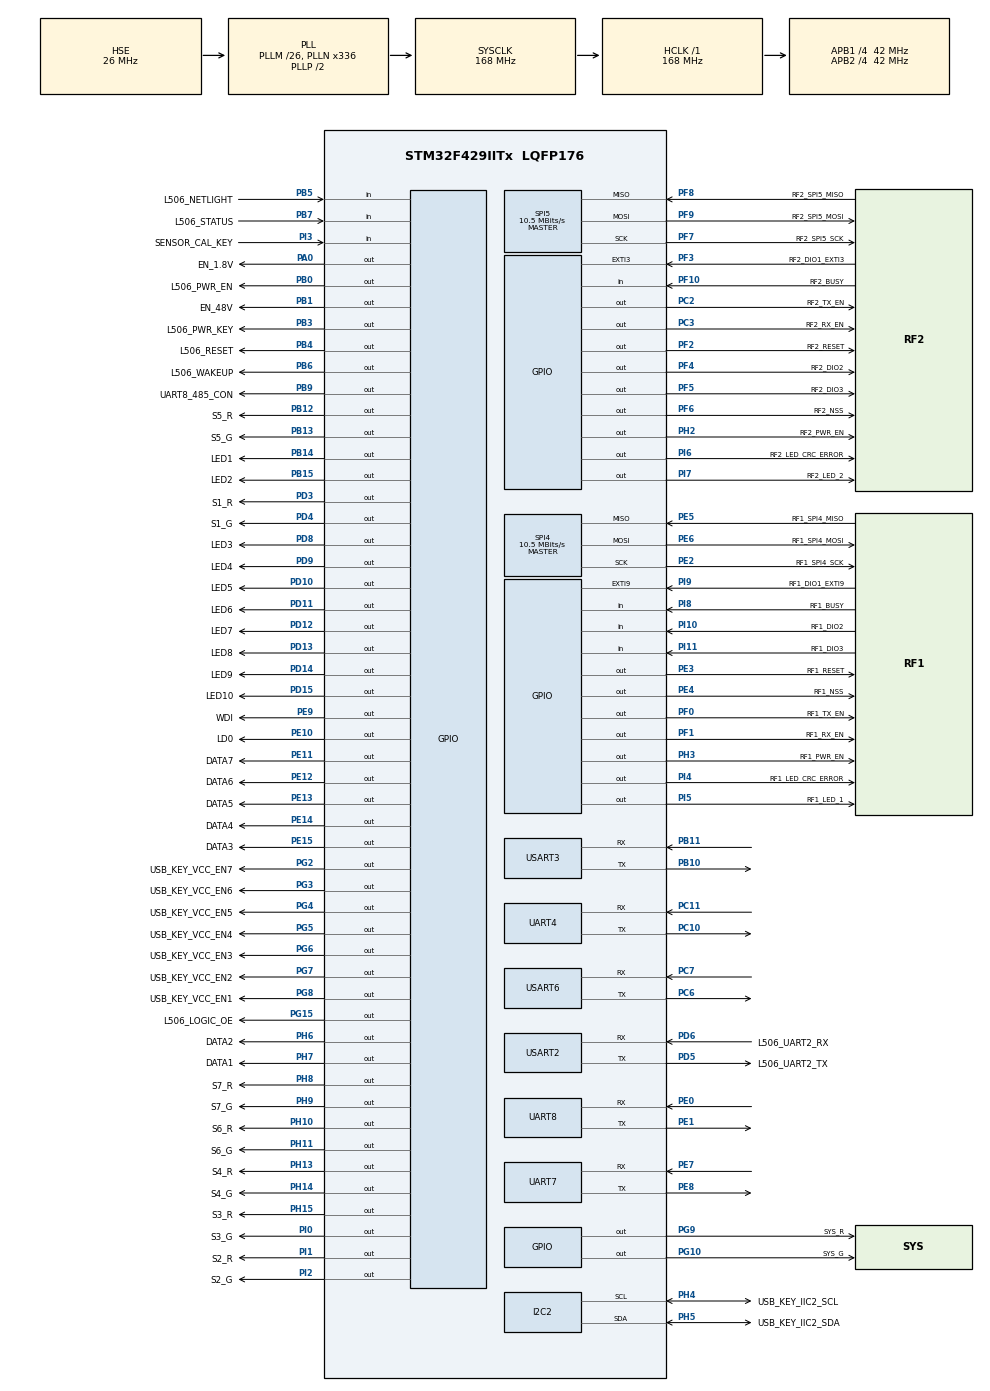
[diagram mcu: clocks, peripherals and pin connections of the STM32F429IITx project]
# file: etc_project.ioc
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Dma.Request0=USART6_RX
Dma.Request1=USART6_TX
Dma.Request2=USART3_TX
Dma.Request3=USART3_RX
Dma.Request4=USART2_RX
Dma.Request5=USART2_TX
Dma.Request6=UART4_RX
Dma.Request7=UART4_TX
Dma.UART4_RX.6.Direction=DMA_PERIPH_TO_MEMORY
Dma.UART4_RX.6.FIFOMode=DMA_FIFOMODE_DISABLE
Dma.UART4_RX.6.Instance=DMA1_Stream2
Dma.UART4_RX.6.MemDataAlignment=DMA_MDATAALIGN_BYTE
Dma.UART4_RX.6.MemInc=DMA_MINC_ENABLE
Dma.UART4_RX.6.Mode=DMA_NORMAL
Dma.UART4_RX.6.PeriphDataAlignment=DMA_PDATAALIGN_BYTE
Dma.UART4_RX.6.PeriphInc=DMA_PINC_DISABLE
Dma.UART4_RX.6.Priority=DMA_PRIORITY_LOW
Dma.UART4_TX.7.Direction=DMA_MEMORY_TO_PERIPH
Dma.UART4_TX.7.FIFOMode=DMA_FIFOMODE_DISABLE
Dma.UART4_TX.7.Instance=DMA1_Stream4
Dma.UART4_TX.7.MemDataAlignment=DMA_MDATAALIGN_BYTE
Dma.UART4_TX.7.MemInc=DMA_MINC_ENABLE
Dma.UART4_TX.7.Mode=DMA_NORMAL
Dma.UART4_TX.7.PeriphDataAlignment=DMA_PDATAALIGN_BYTE
Dma.UART4_TX.7.PeriphInc=DMA_PINC_DISABLE
Dma.UART4_TX.7.Priority=DMA_PRIORITY_LOW
Dma.USART2_RX.4.Direction=DMA_PERIPH_TO_MEMORY
Dma.USART2_RX.4.FIFOMode=DMA_FIFOMODE_DISABLE
Dma.USART2_RX.4.Instance=DMA1_Stream5
Dma.USART2_RX.4.MemDataAlignment=DMA_MDATAALIGN_BYTE
Dma.USART2_RX.4.MemInc=DMA_MINC_ENABLE
Dma.USART2_RX.4.Mode=DMA_NORMAL
Dma.USART2_RX.4.PeriphDataAlignment=DMA_PDATAALIGN_BYTE
Dma.USART2_RX.4.PeriphInc=DMA_PINC_DISABLE
Dma.USART2_RX.4.Priority=DMA_PRIORITY_MEDIUM
Dma.USART2_TX.5.Direction=DMA_MEMORY_TO_PERIPH
Dma.USART2_TX.5.FIFOMode=DMA_FIFOMODE_DISABLE
Dma.USART2_TX.5.Instance=DMA1_Stream6
Dma.USART2_TX.5.MemDataAlignment=DMA_MDATAALIGN_BYTE
Dma.USART2_TX.5.MemInc=DMA_MINC_ENABLE
Dma.USART2_TX.5.Mode=DMA_NORMAL
Dma.USART2_TX.5.PeriphDataAlignment=DMA_PDATAALIGN_BYTE
Dma.USART2_TX.5.PeriphInc=DMA_PINC_DISABLE
Dma.USART2_TX.5.Priority=DMA_PRIORITY_MEDIUM
Dma.USART3_RX.3.Direction=DMA_PERIPH_TO_MEMORY
Dma.USART3_RX.3.FIFOMode=DMA_FIFOMODE_DISABLE
Dma.USART3_RX.3.Instance=DMA1_Stream1
Dma.USART3_RX.3.MemDataAlignment=DMA_MDATAALIGN_BYTE
Dma.USART3_RX.3.MemInc=DMA_MINC_ENABLE
Dma.USART3_RX.3.Mode=DMA_NORMAL
Dma.USART3_RX.3.PeriphDataAlignment=DMA_PDATAALIGN_BYTE
Dma.USART3_RX.3.PeriphInc=DMA_PINC_DISABLE
Dma.USART3_RX.3.Priority=DMA_PRIORITY_LOW
Dma.USART3_TX.2.Direction=DMA_MEMORY_TO_PERIPH
Dma.USART3_TX.2.FIFOMode=DMA_FIFOMODE_DISABLE
Dma.USART3_TX.2.Instance=DMA1_Stream3
Dma.USART3_TX.2.MemDataAlignment=DMA_MDATAALIGN_BYTE
Dma.USART3_TX.2.MemInc=DMA_MINC_ENABLE
Dma.USART3_TX.2.Mode=DMA_NORMAL
Dma.USART3_TX.2.PeriphDataAlignment=DMA_PDATAALIGN_BYTE
Dma.USART3_TX.2.PeriphInc=DMA_PINC_DISABLE
Dma.USART3_TX.2.Priority=DMA_PRIORITY_LOW
Dma.USART6_RX.0.Direction=DMA_PERIPH_TO_MEMORY
Dma.USART6_RX.0.FIFOMode=DMA_FIFOMODE_DISABLE
Dma.USART6_RX.0.Instance=DMA2_Stream1
Dma.USART6_RX.0.MemDataAlignment=DMA_MDATAALIGN_BYTE
Dma.USART6_RX.0.MemInc=DMA_MINC_ENABLE
Dma.USART6_RX.0.Mode=DMA_NORMAL
Dma.USART6_RX.0.PeriphDataAlignment=DMA_PDATAALIGN_BYTE
Dma.USART6_RX.0.PeriphInc=DMA_PINC_DISABLE
Dma.USART6_RX.0.Priority=DMA_PRIORITY_LOW
Dma.USART6_TX.1.Direction=DMA_MEMORY_TO_PERIPH
Dma.USART6_TX.1.FIFOMode=DMA_FIFOMODE_DISABLE
Dma.USART6_TX.1.Instance=DMA2_Stream6
Dma.USART6_TX.1.MemDataAlignment=DMA_MDATAALIGN_BYTE
Dma.USART6_TX.1.MemInc=DMA_MINC_ENABLE
Dma.USART6_TX.1.Mode=DMA_NORMAL
Dma.USART6_TX.1.PeriphDataAlignment=DMA_PDATAALIGN_BYTE
Dma.USART6_TX.1.PeriphInc=DMA_PINC_DISABLE
Dma.USART6_TX.1.Priority=DMA_PRIORITY_LOW
FREERTOS.Tasks01=defaultTask,24,512,StartDefaultTask,Default,NULL,Dynamic,NULL,NULL;t4G_uart_rev_h,26,512,task_4g_uart_rev_handle,As external,NULL,Dynamic,NULL,NULL;uart_debug_send,16,128,task_uart_debug_send,As external,NULL,Dynamic,NULL,NULL;uart_debug_rev,8,128,task_uart_debug_rev_handle,As external,NULL,Dynamic,NULL,NULL
FREERTOS.configLIBRARY_MAX_SYSCALL_INTERRUPT_PRIORITY=3
FREERTOS.configMINIMAL_STACK_SIZE=128
FREERTOS.configTICK_RATE_HZ=100
FREERTOS.configTOTAL_HEAP_SIZE=128000
FREERTOS.configUSE_IDLE_HOOK=0
Mcu.Family=STM32F4
Mcu.Name=STM32F429IITx
Mcu.Package=LQFP176
NVIC.DMA1_Stream1_IRQn=true\:5\:0\:true\:false\:true\:true\:false\:true
NVIC.DMA1_Stream2_IRQn=true\:3\:0\:false\:false\:true\:true\:false\:true
NVIC.DMA1_Stream3_IRQn=true\:3\:0\:false\:false\:true\:true\:false\:true
NVIC.DMA1_Stream4_IRQn=true\:5\:0\:true\:false\:true\:true\:false\:true
NVIC.DMA1_Stream5_IRQn=true\:5\:0\:true\:false\:true\:true\:false\:true
NVIC.DMA1_Stream6_IRQn=true\:5\:0\:true\:false\:true\:true\:false\:true
NVIC.DMA2_Stream1_IRQn=true\:5\:0\:true\:false\:true\:true\:false\:true
NVIC.DMA2_Stream6_IRQn=true\:5\:0\:true\:false\:true\:true\:false\:true
NVIC.EXTI3_IRQn=true\:6\:0\:true\:false\:true\:true\:true\:true
NVIC.EXTI9_5_IRQn=true\:5\:0\:true\:false\:true\:true\:true\:true
NVIC.I2C2_ER_IRQn=true\:5\:0\:true\:false\:true\:true\:true\:true
NVIC.I2C2_EV_IRQn=true\:5\:0\:true\:false\:true\:true\:true\:true
NVIC.PriorityGroup=NVIC_PRIORITYGROUP_4
NVIC.TIM1_UP_TIM10_IRQn=true\:0\:0\:false\:false\:true\:false\:false\:true
NVIC.TimeBase=TIM1_UP_TIM10_IRQn
NVIC.TimeBaseIP=TIM1
NVIC.UART4_IRQn=true\:5\:0\:true\:false\:true\:true\:true\:true
NVIC.UART7_IRQn=true\:9\:0\:true\:false\:true\:true\:true\:true
NVIC.UART8_IRQn=true\:13\:0\:true\:false\:true\:true\:true\:true
NVIC.USART2_IRQn=true\:5\:0\:true\:false\:true\:true\:true\:true
NVIC.USART3_IRQn=true\:5\:0\:true\:false\:true\:true\:true\:true
NVIC.USART6_IRQn=true\:6\:0\:true\:false\:true\:true\:true\:true
PA0/WKUP.GPIO_Label=EN_1.8V
PA0/WKUP.GPIO_ModeDefaultOutputPP=GPIO_MODE_OUTPUT_PP
PA0/WKUP.GPIO_PuPd=GPIO_PULLUP
PA0/WKUP.GPIO_Speed=GPIO_SPEED_FREQ_MEDIUM
PA0/WKUP.PinState=GPIO_PIN_SET
PA0/WKUP.Signal=GPIO_Output
PA13.Mode=Serial_Wire
PA13.Signal=SYS_JTMS-SWDIO
PA14.Mode=Serial_Wire
PA14.Signal=SYS_JTCK-SWCLK
PB0.GPIO_Label=L506_PWR_EN
PB0.GPIO_ModeDefaultOutputPP=GPIO_MODE_OUTPUT_PP
PB0.GPIO_PuPd=GPIO_PULLUP
PB0.GPIO_Speed=GPIO_SPEED_FREQ_MEDIUM
PB0.PinState=GPIO_PIN_SET
PB0.Signal=GPIO_Output
PB1.GPIO_Label=EN_48V
PB1.GPIO_ModeDefaultOutputPP=GPIO_MODE_OUTPUT_PP
PB1.GPIO_PuPd=GPIO_PULLUP
PB1.GPIO_Speed=GPIO_SPEED_FREQ_MEDIUM
PB1.PinState=GPIO_PIN_SET
PB1.Signal=GPIO_Output
PB10.Mode=Asynchronous
PB10.Signal=USART3_TX
PB11.Mode=Asynchronous
PB11.Signal=USART3_RX
PB12.GPIO_Label=S5_R
PB12.GPIO_ModeDefaultOutputPP=GPIO_MODE_OUTPUT_OD
PB12.GPIO_PuPd=GPIO_NOPULL
PB12.GPIO_Speed=GPIO_SPEED_FREQ_HIGH
PB12.PinState=GPIO_PIN_SET
PB12.Signal=GPIO_Output
PB13.GPIO_Label=S5_G
PB13.GPIO_ModeDefaultOutputPP=GPIO_MODE_OUTPUT_OD
PB13.GPIO_PuPd=GPIO_NOPULL
PB13.GPIO_Speed=GPIO_SPEED_FREQ_HIGH
PB13.PinState=GPIO_PIN_SET
PB13.Signal=GPIO_Output
PB14.GPIO_Label=LED1
PB14.GPIO_ModeDefaultOutputPP=GPIO_MODE_OUTPUT_OD
PB14.GPIO_Speed=GPIO_SPEED_FREQ_HIGH
PB14.PinState=GPIO_PIN_SET
PB14.Signal=GPIO_Output
PB15.GPIO_Label=LED2
PB15.GPIO_ModeDefaultOutputPP=GPIO_MODE_OUTPUT_OD
PB15.GPIO_Speed=GPIO_SPEED_FREQ_HIGH
PB15.PinState=GPIO_PIN_SET
PB15.Signal=GPIO_Output
PB3.GPIO_Label=L506_PWR_KEY
PB3.GPIO_ModeDefaultOutputPP=GPIO_MODE_OUTPUT_PP
PB3.GPIO_PuPd=GPIO_PULLUP
PB3.GPIO_Speed=GPIO_SPEED_FREQ_HIGH
PB3.PinState=GPIO_PIN_SET
PB3.Signal=GPIO_Output
PB4.GPIO_Label=L506_RESET
PB4.GPIO_ModeDefaultOutputPP=GPIO_MODE_OUTPUT_PP
PB4.GPIO_PuPd=GPIO_PULLUP
PB4.GPIO_Speed=GPIO_SPEED_FREQ_HIGH
PB4.PinState=GPIO_PIN_SET
PB4.Signal=GPIO_Output
PB5.GPIO_Label=L506_NETLIGHT
PB5.GPIO_PuPd=GPIO_PULLUP
PB5.Signal=GPIO_Input
PB6.GPIO_Label=L506_WAKEUP
PB6.GPIO_ModeDefaultOutputPP=GPIO_MODE_OUTPUT_PP
PB6.GPIO_PuPd=GPIO_PULLUP
PB6.GPIO_Speed=GPIO_SPEED_FREQ_HIGH
PB6.PinState=GPIO_PIN_SET
PB6.Signal=GPIO_Output
PB7.GPIO_Label=L506_STATUS
PB7.GPIO_PuPd=GPIO_PULLUP
PB7.Signal=GPIO_Input
PB9.GPIO_Label=UART8_485_CON
PB9.GPIO_ModeDefaultOutputPP=GPIO_MODE_OUTPUT_PP
PB9.GPIO_PuPd=GPIO_PULLUP
PB9.GPIO_Speed=GPIO_SPEED_FREQ_VERY_HIGH
PB9.PinState=GPIO_PIN_SET
PB9.Signal=GPIO_Output
PC10.Mode=Asynchronous
PC10.Signal=UART4_TX
PC11.Mode=Asynchronous
PC11.Signal=UART4_RX
PC14/OSC32_IN.Mode=LSE-External-Clock-Source
PC14/OSC32_IN.Signal=RCC_OSC32_IN
PC15/OSC32_OUT.Mode=LSE-External-Clock-Source
PC15/OSC32_OUT.Signal=RCC_OSC32_OUT
PC2.GPIO_Label=RF2_TX_EN
PC2.GPIO_ModeDefaultOutputPP=GPIO_MODE_OUTPUT_PP
PC2.GPIO_PuPd=GPIO_PULLUP
PC2.GPIO_Speed=GPIO_SPEED_FREQ_VERY_HIGH
PC2.PinState=GPIO_PIN_SET
PC2.Signal=GPIO_Output
PC3.GPIO_Label=RF2_RX_EN
PC3.GPIO_ModeDefaultOutputPP=GPIO_MODE_OUTPUT_PP
PC3.GPIO_PuPd=GPIO_PULLUP
PC3.GPIO_Speed=GPIO_SPEED_FREQ_VERY_HIGH
PC3.PinState=GPIO_PIN_SET
PC3.Signal=GPIO_Output
PC6.Mode=Asynchronous
PC6.Signal=USART6_TX
PC7.Mode=Asynchronous
PC7.Signal=USART6_RX
PD10.GPIO_Label=LED5
PD10.GPIO_ModeDefaultOutputPP=GPIO_MODE_OUTPUT_OD
PD10.GPIO_PuPd=GPIO_NOPULL
PD10.GPIO_Speed=GPIO_SPEED_FREQ_HIGH
PD10.PinState=GPIO_PIN_SET
PD10.Signal=GPIO_Output
PD11.GPIO_Label=LED6
PD11.GPIO_ModeDefaultOutputPP=GPIO_MODE_OUTPUT_OD
PD11.GPIO_Speed=GPIO_SPEED_FREQ_HIGH
PD11.PinState=GPIO_PIN_SET
PD11.Signal=GPIO_Output
PD12.GPIO_Label=LED7
PD12.GPIO_ModeDefaultOutputPP=GPIO_MODE_OUTPUT_OD
PD12.GPIO_Speed=GPIO_SPEED_FREQ_HIGH
PD12.PinState=GPIO_PIN_SET
PD12.Signal=GPIO_Output
PD13.GPIO_Label=LED8
PD13.GPIO_ModeDefaultOutputPP=GPIO_MODE_OUTPUT_OD
PD13.GPIO_Speed=GPIO_SPEED_FREQ_HIGH
PD13.PinState=GPIO_PIN_SET
PD13.Signal=GPIO_Output
PD14.GPIO_Label=LED9
PD14.GPIO_ModeDefaultOutputPP=GPIO_MODE_OUTPUT_OD
PD14.GPIO_Speed=GPIO_SPEED_FREQ_HIGH
PD14.PinState=GPIO_PIN_SET
PD14.Signal=GPIO_Output
PD15.GPIO_Label=LED10
PD15.GPIO_ModeDefaultOutputPP=GPIO_MODE_OUTPUT_OD
PD15.GPIO_Speed=GPIO_SPEED_FREQ_HIGH
PD15.PinState=GPIO_PIN_SET
PD15.Signal=GPIO_Output
PD3.GPIO_Label=S1_R
PD3.GPIO_ModeDefaultOutputPP=GPIO_MODE_OUTPUT_OD
PD3.GPIO_PuPd=GPIO_NOPULL
PD3.GPIO_Speed=GPIO_SPEED_FREQ_HIGH
PD3.PinState=GPIO_PIN_SET
PD3.Signal=GPIO_Output
PD4.GPIO_Label=S1_G
PD4.GPIO_ModeDefaultOutputPP=GPIO_MODE_OUTPUT_OD
PD4.GPIO_PuPd=GPIO_NOPULL
PD4.GPIO_Speed=GPIO_SPEED_FREQ_HIGH
PD4.PinState=GPIO_PIN_SET
PD4.Signal=GPIO_Output
PD5.GPIO_Label=L506_UART2_TX
PD5.Mode=Asynchronous
PD5.Signal=USART2_TX
PD6.GPIO_Label=L506_UART2_RX
PD6.Mode=Asynchronous
PD6.Signal=USART2_RX
PD8.GPIO_Label=LED3
PD8.GPIO_ModeDefaultOutputPP=GPIO_MODE_OUTPUT_OD
PD8.GPIO_PuPd=GPIO_NOPULL
PD8.GPIO_Speed=GPIO_SPEED_FREQ_HIGH
PD8.PinState=GPIO_PIN_SET
PD8.Signal=GPIO_Output
PD9.GPIO_Label=LED4
PD9.GPIO_ModeDefaultOutputPP=GPIO_MODE_OUTPUT_OD
PD9.GPIO_Speed=GPIO_SPEED_FREQ_HIGH
PD9.PinState=GPIO_PIN_SET
PD9.Signal=GPIO_Output
PE0.Mode=Asynchronous
PE0.Signal=UART8_RX
PE1.Mode=Asynchronous
PE1.Signal=UART8_TX
PE10.GPIO_Label=LD0
PE10.GPIO_ModeDefaultOutputPP=GPIO_MODE_OUTPUT_PP
PE10.GPIO_PuPd=GPIO_PULLUP
PE10.GPIO_Speed=GPIO_SPEED_FREQ_VERY_HIGH
PE10.PinState=GPIO_PIN_SET
PE10.Signal=GPIO_Output
PE11.GPIO_Label=DATA7
PE11.GPIO_ModeDefaultOutputPP=GPIO_MODE_OUTPUT_PP
PE11.GPIO_PuPd=GPIO_PULLUP
PE11.GPIO_Speed=GPIO_SPEED_FREQ_VERY_HIGH
PE11.PinState=GPIO_PIN_SET
PE11.Signal=GPIO_Output
PE12.GPIO_Label=DATA6
PE12.GPIO_ModeDefaultOutputPP=GPIO_MODE_OUTPUT_PP
PE12.GPIO_PuPd=GPIO_PULLUP
PE12.GPIO_Speed=GPIO_SPEED_FREQ_VERY_HIGH
PE12.PinState=GPIO_PIN_SET
PE12.Signal=GPIO_Output
PE13.GPIO_Label=DATA5
PE13.GPIO_PuPd=GPIO_PULLUP
PE13.GPIO_Speed=GPIO_SPEED_FREQ_VERY_HIGH
PE13.PinState=GPIO_PIN_SET
PE13.Signal=GPIO_Output
PE14.GPIO_Label=DATA4
PE14.GPIO_PuPd=GPIO_PULLUP
PE14.GPIO_Speed=GPIO_SPEED_FREQ_VERY_HIGH
PE14.PinState=GPIO_PIN_SET
PE14.Signal=GPIO_Output
PE15.GPIO_Label=DATA3
PE15.GPIO_PuPd=GPIO_PULLUP
PE15.GPIO_Speed=GPIO_SPEED_FREQ_VERY_HIGH
PE15.PinState=GPIO_PIN_SET
PE15.Signal=GPIO_Output
PE2.GPIO_Label=RF1_SPI4_SCK
PE2.Mode=Full_Duplex_Master
PE2.Signal=SPI4_SCK
PE3.GPIO_Label=RF1_RESET
PE3.GPIO_ModeDefaultOutputPP=GPIO_MODE_OUTPUT_PP
PE3.GPIO_PuPd=GPIO_PULLUP
PE3.GPIO_Speed=GPIO_SPEED_FREQ_VERY_HIGH
PE3.PinState=GPIO_PIN_SET
PE3.Signal=GPIO_Output
PE4.GPIO_Label=RF1_NSS
PE4.GPIO_ModeDefaultOutputPP=GPIO_MODE_OUTPUT_PP
PE4.GPIO_PuPd=GPIO_PULLUP
PE4.GPIO_Speed=GPIO_SPEED_FREQ_VERY_HIGH
PE4.PinState=GPIO_PIN_SET
PE4.Signal=GPIO_Output
PE5.GPIO_Label=RF1_SPI4_MISO
PE5.Mode=Full_Duplex_Master
PE5.Signal=SPI4_MISO
PE6.GPIO_Label=RF1_SPI4_MOSI
PE6.Mode=Full_Duplex_Master
PE6.Signal=SPI4_MOSI
PE7.Mode=Asynchronous
PE7.Signal=UART7_RX
PE8.Mode=Asynchronous
PE8.Signal=UART7_TX
PE9.GPIO_Label=WDI
PE9.GPIO_ModeDefaultOutputPP=GPIO_MODE_OUTPUT_PP
PE9.GPIO_PuPd=GPIO_NOPULL
PE9.GPIO_Speed=GPIO_SPEED_FREQ_VERY_HIGH
PE9.PinState=GPIO_PIN_SET
PE9.Signal=GPIO_Output
PF0.GPIO_Label=RF1_TX_EN
PF0.GPIO_PuPd=GPIO_PULLUP
PF0.GPIO_Speed=GPIO_SPEED_FREQ_VERY_HIGH
PF0.PinState=GPIO_PIN_SET
PF0.Signal=GPIO_Output
PF1.GPIO_Label=RF1_RX_EN
PF1.GPIO_ModeDefaultOutputPP=GPIO_MODE_OUTPUT_PP
PF1.GPIO_PuPd=GPIO_PULLUP
PF1.GPIO_Speed=GPIO_SPEED_FREQ_VERY_HIGH
PF1.PinState=GPIO_PIN_SET
PF1.Signal=GPIO_Output
PF10.GPIO_Label=RF2_BUSY
PF10.GPIO_PuPd=GPIO_PULLUP
PF10.Signal=GPIO_Input
PF2.GPIO_Label=RF2_RESET
PF2.GPIO_ModeDefaultOutputPP=GPIO_MODE_OUTPUT_PP
PF2.GPIO_PuPd=GPIO_PULLUP
PF2.GPIO_Speed=GPIO_SPEED_FREQ_VERY_HIGH
PF2.PinState=GPIO_PIN_SET
PF2.Signal=GPIO_Output
PF3.GPIO_Label=RF2_DIO1_EXTI3
PF3.Signal=GPXTI3
PF4.GPIO_Label=RF2_DIO2
PF4.Signal=GPIO_Output
PF5.GPIO_Label=RF2_DIO3
PF5.Signal=GPIO_Output
PF6.GPIO_Label=RF2_NSS
PF6.GPIO_ModeDefaultOutputPP=GPIO_MODE_OUTPUT_PP
PF6.GPIO_PuPd=GPIO_PULLUP
PF6.GPIO_Speed=GPIO_SPEED_FREQ_VERY_HIGH
PF6.PinState=GPIO_PIN_SET
PF6.Signal=GPIO_Output
PF7.GPIO_Label=RF2_SPI5_SCK
PF7.Mode=Full_Duplex_Master
PF7.Signal=SPI5_SCK
PF8.GPIO_Label=RF2_SPI5_MISO
PF8.Mode=Full_Duplex_Master
PF8.Signal=SPI5_MISO
PF9.GPIO_Label=RF2_SPI5_MOSI
PF9.Mode=Full_Duplex_Master
PF9.Signal=SPI5_MOSI
PG10.GPIO_Label=SYS_G
PG10.GPIO_ModeDefaultOutputPP=GPIO_MODE_OUTPUT_OD
PG10.GPIO_Speed=GPIO_SPEED_FREQ_HIGH
PG10.PinState=GPIO_PIN_SET
PG10.Signal=GPIO_Output
PG15.GPIO_Label=L506_LOGIC_OE
PG15.GPIO_ModeDefaultOutputPP=GPIO_MODE_OUTPUT_PP
PG15.GPIO_PuPd=GPIO_PULLUP
PG15.GPIO_Speed=GPIO_SPEED_FREQ_HIGH
PG15.Signal=GPIO_Output
PG2.GPIO_Label=USB_KEY_VCC_EN7
PG2.GPIO_ModeDefaultOutputPP=GPIO_MODE_OUTPUT_PP
PG2.GPIO_PuPd=GPIO_PULLUP
PG2.GPIO_Speed=GPIO_SPEED_FREQ_VERY_HIGH
PG2.PinState=GPIO_PIN_RESET
PG2.Signal=GPIO_Output
PG3.GPIO_Label=USB_KEY_VCC_EN6
PG3.GPIO_PuPd=GPIO_PULLUP
PG3.GPIO_Speed=GPIO_SPEED_FREQ_VERY_HIGH
PG3.PinState=GPIO_PIN_RESET
PG3.Signal=GPIO_Output
PG4.GPIO_Label=USB_KEY_VCC_EN5
PG4.GPIO_PuPd=GPIO_PULLUP
PG4.GPIO_Speed=GPIO_SPEED_FREQ_VERY_HIGH
PG4.PinState=GPIO_PIN_RESET
PG4.Signal=GPIO_Output
PG5.GPIO_Label=USB_KEY_VCC_EN4
PG5.GPIO_PuPd=GPIO_PULLUP
PG5.GPIO_Speed=GPIO_SPEED_FREQ_VERY_HIGH
PG5.Signal=GPIO_Output
PG6.GPIO_Label=USB_KEY_VCC_EN3
PG6.GPIO_PuPd=GPIO_PULLUP
PG6.GPIO_Speed=GPIO_SPEED_FREQ_VERY_HIGH
PG6.Signal=GPIO_Output
PG7.GPIO_Label=USB_KEY_VCC_EN2
PG7.GPIO_PuPd=GPIO_PULLUP
PG7.GPIO_Speed=GPIO_SPEED_FREQ_VERY_HIGH
PG7.Signal=GPIO_Output
PG8.GPIO_Label=USB_KEY_VCC_EN1
PG8.GPIO_PuPd=GPIO_PULLUP
PG8.GPIO_Speed=GPIO_SPEED_FREQ_VERY_HIGH
PG8.Signal=GPIO_Output
PG9.GPIO_Label=SYS_R
PG9.GPIO_ModeDefaultOutputPP=GPIO_MODE_OUTPUT_OD
PG9.GPIO_PuPd=GPIO_NOPULL
PG9.GPIO_Speed=GPIO_SPEED_FREQ_HIGH
PG9.PinState=GPIO_PIN_SET
PG9.Signal=GPIO_Output
PH0/OSC_IN.Mode=HSE-External-Clock-Source
PH0/OSC_IN.Signal=RCC_OSC_IN
PH1/OSC_OUT.Mode=HSE-External-Clock-Source
PH1/OSC_OUT.Signal=RCC_OSC_OUT
PH10.GPIO_Label=S6_R
PH10.GPIO_ModeDefaultOutputPP=GPIO_MODE_OUTPUT_PP
PH10.GPIO_PuPd=GPIO_PULLUP
PH10.GPIO_Speed=GPIO_SPEED_FREQ_VERY_HIGH
PH10.PinState=GPIO_PIN_SET
PH10.Signal=GPIO_Output
PH11.GPIO_Label=S6_G
PH11.GPIO_ModeDefaultOutputPP=GPIO_MODE_OUTPUT_PP
PH11.GPIO_PuPd=GPIO_PULLUP
PH11.GPIO_Speed=GPIO_SPEED_FREQ_VERY_HIGH
PH11.PinState=GPIO_PIN_SET
PH11.Signal=GPIO_Output
PH13.GPIO_Label=S4_R
PH13.GPIO_ModeDefaultOutputPP=GPIO_MODE_OUTPUT_PP
PH13.GPIO_PuPd=GPIO_PULLUP
PH13.GPIO_Speed=GPIO_SPEED_FREQ_VERY_HIGH
PH13.PinState=GPIO_PIN_SET
PH13.Signal=GPIO_Output
PH14.GPIO_Label=S4_G
PH14.GPIO_PuPd=GPIO_PULLUP
PH14.GPIO_Speed=GPIO_SPEED_FREQ_VERY_HIGH
PH14.PinState=GPIO_PIN_SET
PH14.Signal=GPIO_Output
PH15.GPIO_Label=S3_R
PH15.GPIO_ModeDefaultOutputPP=GPIO_MODE_OUTPUT_PP
PH15.GPIO_PuPd=GPIO_PULLUP
PH15.GPIO_Speed=GPIO_SPEED_FREQ_VERY_HIGH
PH15.PinState=GPIO_PIN_SET
PH15.Signal=GPIO_Output
PH2.GPIO_Label=RF2_PWR_EN
PH2.GPIO_ModeDefaultOutputPP=GPIO_MODE_OUTPUT_PP
PH2.GPIO_PuPd=GPIO_PULLUP
PH2.GPIO_Speed=GPIO_SPEED_FREQ_HIGH
PH2.PinState=GPIO_PIN_SET
PH2.Signal=GPIO_Output
PH3.GPIO_Label=RF1_PWR_EN
PH3.GPIO_ModeDefaultOutputPP=GPIO_MODE_OUTPUT_PP
PH3.GPIO_PuPd=GPIO_PULLUP
PH3.GPIO_Speed=GPIO_SPEED_FREQ_HIGH
PH3.PinState=GPIO_PIN_SET
PH3.Signal=GPIO_Output
PH4.GPIO_Label=USB_KEY_IIC2_SCL
PH4.Mode=I2C
PH4.Signal=I2C2_SCL
PH5.GPIO_Label=USB_KEY_IIC2_SDA
PH5.Mode=I2C
PH5.Signal=I2C2_SDA
PH6.GPIO_Label=DATA2
PH6.GPIO_ModeDefaultOutputPP=GPIO_MODE_OUTPUT_PP
PH6.GPIO_PuPd=GPIO_PULLUP
PH6.GPIO_Speed=GPIO_SPEED_FREQ_VERY_HIGH
PH6.PinState=GPIO_PIN_SET
PH6.Signal=GPIO_Output
PH7.GPIO_Label=DATA1
PH7.GPIO_PuPd=GPIO_PULLUP
PH7.GPIO_Speed=GPIO_SPEED_FREQ_VERY_HIGH
PH7.PinState=GPIO_PIN_SET
PH7.Signal=GPIO_Output
PH8.GPIO_Label=S7_R
PH8.GPIO_ModeDefaultOutputPP=GPIO_MODE_OUTPUT_PP
PH8.GPIO_PuPd=GPIO_PULLUP
PH8.GPIO_Speed=GPIO_SPEED_FREQ_VERY_HIGH
PH8.PinState=GPIO_PIN_SET
PH8.Signal=GPIO_Output
PH9.GPIO_Label=S7_G
PH9.GPIO_ModeDefaultOutputPP=GPIO_MODE_OUTPUT_PP
PH9.GPIO_PuPd=GPIO_PULLUP
PH9.GPIO_Speed=GPIO_SPEED_FREQ_VERY_HIGH
PH9.PinState=GPIO_PIN_SET
PH9.Signal=GPIO_Output
PI0.GPIO_Label=S3_G
PI0.GPIO_ModeDefaultOutputPP=GPIO_MODE_OUTPUT_PP
PI0.GPIO_PuPd=GPIO_PULLUP
PI0.GPIO_Speed=GPIO_SPEED_FREQ_VERY_HIGH
PI0.PinState=GPIO_PIN_SET
PI0.Signal=GPIO_Output
PI1.GPIO_Label=S2_R
PI1.GPIO_ModeDefaultOutputPP=GPIO_MODE_OUTPUT_PP
PI1.GPIO_PuPd=GPIO_PULLUP
PI1.GPIO_Speed=GPIO_SPEED_FREQ_VERY_HIGH
PI1.PinState=GPIO_PIN_SET
PI1.Signal=GPIO_Output
PI10.GPIO_Label=RF1_DIO2
PI10.GPIO_PuPd=GPIO_PULLUP
PI10.Signal=GPIO_Input
PI11.GPIO_Label=RF1_DIO3
PI11.GPIO_PuPd=GPIO_PULLUP
PI11.Signal=GPIO_Input
PI2.GPIO_Label=S2_G
PI2.GPIO_ModeDefaultOutputPP=GPIO_MODE_OUTPUT_PP
PI2.GPIO_PuPd=GPIO_PULLUP
PI2.GPIO_Speed=GPIO_SPEED_FREQ_VERY_HIGH
PI2.PinState=GPIO_PIN_SET
PI2.Signal=GPIO_Output
PI3.GPIO_Label=SENSOR_CAL_KEY
PI3.GPIO_PuPd=GPIO_PULLUP
PI3.Signal=GPIO_Input
PI4.GPIO_Label=RF1_LED_CRC_ERROR
PI4.GPIO_ModeDefaultOutputPP=GPIO_MODE_OUTPUT_OD
PI4.GPIO_Speed=GPIO_SPEED_FREQ_VERY_HIGH
PI4.PinState=GPIO_PIN_SET
PI4.Signal=GPIO_Output
PI5.GPIO_Label=RF1_LED_1
PI5.GPIO_ModeDefaultOutputPP=GPIO_MODE_OUTPUT_OD
PI5.GPIO_Speed=GPIO_SPEED_FREQ_VERY_HIGH
PI5.PinState=GPIO_PIN_SET
PI5.Signal=GPIO_Output
PI6.GPIO_Label=RF2_LED_CRC_ERROR
PI6.GPIO_ModeDefaultOutputPP=GPIO_MODE_OUTPUT_OD
PI6.GPIO_Speed=GPIO_SPEED_FREQ_VERY_HIGH
PI6.PinState=GPIO_PIN_SET
PI6.Signal=GPIO_Output
PI7.GPIO_Label=RF2_LED_2
PI7.GPIO_ModeDefaultOutputPP=GPIO_MODE_OUTPUT_OD
PI7.GPIO_Speed=GPIO_SPEED_FREQ_VERY_HIGH
PI7.PinState=GPIO_PIN_SET
PI7.Signal=GPIO_Output
PI8.GPIO_Label=RF1_BUSY
PI8.GPIO_PuPd=GPIO_PULLUP
PI8.Signal=GPIO_Input
PI9.GPIO_Label=RF1_DIO1_EXTI9
PI9.GPIO_ModeDefaultEXTI=GPIO_MODE_IT_RISING
PI9.GPIO_PuPd=GPIO_NOPULL
PI9.Signal=GPXTI9
ProjectManager.HeapSize=0x200
ProjectManager.StackSize=0x2000
ProjectManager.TargetToolchain=MDK-ARM V5
RCC.48MHZClocksFreq_Value=84000000
RCC.AHBFreq_Value=168000000
RCC.APB1CLKDivider=RCC_HCLK_DIV4
RCC.APB1Freq_Value=42000000
RCC.APB1TimFreq_Value=84000000
RCC.APB2CLKDivider=RCC_HCLK_DIV4
RCC.APB2Freq_Value=42000000
RCC.APB2TimFreq_Value=84000000
RCC.CortexFreq_Value=168000000
RCC.EnbaleCSS=true
RCC.HCLKFreq_Value=168000000
RCC.HSE_VALUE=26000000
RCC.HSI_VALUE=16000000
RCC.LSE_VALUE=32768
RCC.PLLM=26
RCC.PLLN=336
RCC.PLLSourceVirtual=RCC_PLLSOURCE_HSE
RCC.RCC_RTC_Clock_Source=RCC_RTCCLKSOURCE_LSE
RCC.RCC_RTC_Clock_SourceVirtual=RCC_RTCCLKSOURCE_LSE
RCC.SYSCLKFreq_VALUE=168000000
RCC.SYSCLKSource=RCC_SYSCLKSOURCE_PLLCLK
RCC.VCOOutputFreq_Value=336000000
SPI4.BaudRatePrescaler=SPI_BAUDRATEPRESCALER_4
SPI4.CalculateBaudRate=10.5 MBits/s
SPI4.Direction=SPI_DIRECTION_2LINES
SPI4.Mode=SPI_MODE_MASTER
SPI4.VirtualType=VM_MASTER
SPI5.BaudRatePrescaler=SPI_BAUDRATEPRESCALER_4
SPI5.CalculateBaudRate=10.5 MBits/s
SPI5.Direction=SPI_DIRECTION_2LINES
SPI5.Mode=SPI_MODE_MASTER
SPI5.VirtualType=VM_MASTER
UART4.VirtualMode=Asynchronous
UART7.VirtualMode=Asynchronous
UART8.VirtualMode=Asynchronous
USART2.VirtualMode=VM_ASYNC
USART3.VirtualMode=VM_ASYNC
USART6.VirtualMode=VM_ASYNC
VP_CRC_VS_CRC.Mode=CRC_Activate
VP_FREERTOS_VS_CMSIS_V2.Mode=CMSIS_V2
VP_RTC_VS_RTC_Activate.Mode=RTC_Enabled
VP_SYS_VS_tim1.Mode=TIM1
board=custom

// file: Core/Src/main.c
/* USER CODE BEGIN Header */
/**
  ******************************************************************************
  * @file           : main.c
  * @brief          : Main program body
  ******************************************************************************
  * @attention
  *
  * <h2><center>&copy; Copyright (c) 2020 STMicroelectronics.
  * All rights reserved.</center></h2>
  *
  * This software component is licensed by ST under Ultimate Liberty license
  * SLA0044, the "License"; You may not use this file except in compliance with
  * the License. You may obtain a copy of the License at:
  *                             www.st.com/SLA0044
  *
  ******************************************************************************
  */
/* USER CODE END Header */

#include "main.h"
#include "cmsis_os.h"
#include "crc.h"
#include "dma.h"
#include "i2c.h"
#include "rtc.h"
#include "spi.h"
#include "usart.h"
#include "gpio.h"

/* USER CODE BEGIN PTD */
extern void rf_init();
/* USER CODE END PTD */

void SystemClock_Config(void);
void MX_FREERTOS_Init(void);

int main(void)
{

  /* MCU Configuration--------------------------------------------------------*/

  /* Reset of all peripherals, Initializes the Flash interface and the Systick. */
  HAL_Init();

  /* Configure the system clock */
  SystemClock_Config();

  /* Initialize all configured peripherals */
  MX_GPIO_Init();
  MX_DMA_Init();
  MX_I2C2_Init();
  MX_RTC_Init();
  MX_SPI4_Init();
  MX_SPI5_Init();
  MX_UART4_Init();
  MX_UART7_Init();
  MX_UART8_Init();
  MX_USART2_UART_Init();
  MX_USART3_UART_Init();
  MX_USART6_UART_Init();
  MX_CRC_Init();
  /* USER CODE BEGIN 2 */
	rf_init();
  /* USER CODE END 2 */

  /* Init scheduler */
  osKernelInitialize();  /* Call init function for freertos objects (in freertos.c) */
  MX_FREERTOS_Init();
  /* Start scheduler */
  osKernelStart();

  /* We should never get here as control is now taken by the scheduler */
  /* Infinite loop */
  while (1)
  {

  }
}

void SystemClock_Config(void)
{
  RCC_OscInitTypeDef RCC_OscInitStruct = {0};
  RCC_ClkInitTypeDef RCC_ClkInitStruct = {0};
  RCC_PeriphCLKInitTypeDef PeriphClkInitStruct = {0};

  /** Configure the main internal regulator output voltage
  */
  __HAL_RCC_PWR_CLK_ENABLE();
  __HAL_PWR_VOLTAGESCALING_CONFIG(PWR_REGULATOR_VOLTAGE_SCALE1);
  /** Initializes the CPU, AHB and APB busses clocks
  */
  RCC_OscInitStruct.OscillatorType = RCC_OSCILLATORTYPE_HSE|RCC_OSCILLATORTYPE_LSE;
  RCC_OscInitStruct.HSEState = RCC_HSE_BYPASS;
  RCC_OscInitStruct.LSEState = RCC_LSE_BYPASS;
  RCC_OscInitStruct.PLL.PLLState = RCC_PLL_ON;
  RCC_OscInitStruct.PLL.PLLSource = RCC_PLLSOURCE_HSE;
  RCC_OscInitStruct.PLL.PLLM = 26;
  RCC_OscInitStruct.PLL.PLLN = 336;
  RCC_OscInitStruct.PLL.PLLP = RCC_PLLP_DIV2;
  RCC_OscInitStruct.PLL.PLLQ = 4;
  if (HAL_RCC_OscConfig(&RCC_OscInitStruct) != HAL_OK)
  {
    Error_Handler();
  }
  /** Initializes the CPU, AHB and APB busses clocks
  */
  RCC_ClkInitStruct.ClockType = RCC_CLOCKTYPE_HCLK|RCC_CLOCKTYPE_SYSCLK
                              |RCC_CLOCKTYPE_PCLK1|RCC_CLOCKTYPE_PCLK2;
  RCC_ClkInitStruct.SYSCLKSource = RCC_SYSCLKSOURCE_PLLCLK;
  RCC_ClkInitStruct.AHBCLKDivider = RCC_SYSCLK_DIV1;
  RCC_ClkInitStruct.APB1CLKDivider = RCC_HCLK_DIV4;
  RCC_ClkInitStruct.APB2CLKDivider = RCC_HCLK_DIV4;

  if (HAL_RCC_ClockConfig(&RCC_ClkInitStruct, FLASH_LATENCY_5) != HAL_OK)
  {
    Error_Handler();
  }
  PeriphClkInitStruct.PeriphClockSelection = RCC_PERIPHCLK_RTC;
  PeriphClkInitStruct.RTCClockSelection = RCC_RTCCLKSOURCE_LSE;
  if (HAL_RCCEx_PeriphCLKConfig(&PeriphClkInitStruct) != HAL_OK)
  {
    Error_Handler();
  }
  /** Enables the Clock Security System
  */
  HAL_RCC_EnableCSS();
}

 /**
  * @brief  Period elapsed callback in non blocking mode
  * @note   This function is called  when TIM1 interrupt took place, inside
  * HAL_TIM_IRQHandler(). It makes a direct call to HAL_IncTick() to increment
  * a global variable "uwTick" used as application time base.
  * @param  htim : TIM handle
  * @retval None
  */
void HAL_TIM_PeriodElapsedCallback(TIM_HandleTypeDef *htim)
{
  if (htim->Instance == TIM1) {
    HAL_IncTick();
  }
}

void Error_Handler(void)
{
}

/************************ (C) COPYRIGHT STMicroelectronics *****END OF FILE****/

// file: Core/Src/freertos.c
/* USER CODE BEGIN Header */
/**
  ******************************************************************************
  * File Name          : freertos.c
  * Description        : Code for freertos applications
  ******************************************************************************
  * @attention
  *
  * <h2><center>&copy; Copyright (c) 2020 STMicroelectronics.
  * All rights reserved.</center></h2>
  *
  * This software component is licensed by ST under Ultimate Liberty license
  * SLA0044, the "License"; You may not use this file except in compliance with
  * the License. You may obtain a copy of the License at:
  *                             www.st.com/SLA0044
  *
  ******************************************************************************
  */
/* USER CODE END Header */

#include "FreeRTOS.h"
#include "task.h"
#include "main.h"
#include "cmsis_os.h"

/* Definitions for defaultTask */
osThreadId_t defaultTaskHandle;
const osThreadAttr_t defaultTask_attributes = {
  .name = "defaultTask",
  .priority = (osPriority_t) osPriorityNormal,
  .stack_size = 512 * 4
};
/* Definitions for t4G_uart_rev_h */
osThreadId_t t4G_uart_rev_hHandle;
const osThreadAttr_t t4G_uart_rev_h_attributes = {
  .name = "t4G_uart_rev_h",
  .priority = (osPriority_t) osPriorityNormal2,
  .stack_size = 512 * 4
};
/* Definitions for uart_debug_send */
osThreadId_t uart_debug_sendHandle;
const osThreadAttr_t uart_debug_send_attributes = {
  .name = "uart_debug_send",
  .priority = (osPriority_t) osPriorityBelowNormal,
  .stack_size = 128 * 4
};
/* Definitions for uart_debug_rev */
osThreadId_t uart_debug_revHandle;
const osThreadAttr_t uart_debug_rev_attributes = {
  .name = "uart_debug_rev",
  .priority = (osPriority_t) osPriorityLow,
  .stack_size = 128 * 4
};

/* USER CODE BEGIN FunctionPrototypes */
osThreadId_t t4G_data_sendHandle;
const osThreadAttr_t t4G_data_send_attributes = {
  .name = "t4G_data_send",
  .priority = (osPriority_t) osPriorityNormal1,
  .stack_size = 128 * 4
};

extern void task_t4G_data_send(void *argument);

osThreadId_t t4G_client_0Handle;
const osThreadAttr_t t4G_dclient_0_attributes = {
  .name = "t4G_client_0",
  .priority = (osPriority_t) osPriorityNormal1,
  .stack_size = 512 * 4
};

extern void task_client_0(void *argument);

osThreadId_t rf_callbackHandle;
const osThreadAttr_t rf_callback_attributes = {
  .name = "rf_callback",
  .priority = (osPriority_t) osPriorityNormal1,
  .stack_size = 512 * 4
};

extern void task_rf_callback(void *argument);

/* USER CODE END FunctionPrototypes */

void StartDefaultTask(void *argument);
extern void task_4g_uart_rev_handle(void *argument);
extern void task_uart_debug_send(void *argument);
extern void task_uart_debug_rev_handle(void *argument);

void MX_FREERTOS_Init(void); /* (MISRA C 2004 rule 8.1) */

void MX_FREERTOS_Init(void) {

  /* Create the thread(s) */
  /* creation of defaultTask */
  defaultTaskHandle = osThreadNew(StartDefaultTask, NULL, &defaultTask_attributes);

  /* creation of t4G_uart_rev_h */
  t4G_uart_rev_hHandle = osThreadNew(task_4g_uart_rev_handle, NULL, &t4G_uart_rev_h_attributes);

  /* creation of uart_debug_send */
  uart_debug_sendHandle = osThreadNew(task_uart_debug_send, NULL, &uart_debug_send_attributes);

  /* creation of uart_debug_rev */
  uart_debug_revHandle = osThreadNew(task_uart_debug_rev_handle, NULL, &uart_debug_rev_attributes);

  /* USER CODE BEGIN RTOS_THREADS */
  t4G_data_sendHandle = osThreadNew(task_t4G_data_send, NULL, &t4G_data_send_attributes);

	t4G_client_0Handle = osThreadNew(task_client_0, NULL, &t4G_dclient_0_attributes);

  rf_callbackHandle = osThreadNew(task_rf_callback, NULL, &rf_callback_attributes);
  /* add threads, ... */
  /* USER CODE END RTOS_THREADS */

}

void StartDefaultTask(void *argument)
{
  /* USER CODE BEGIN StartDefaultTask */
	uint32_t delay = 0;
  /* Infinite loop */
  for(;;)
  {
    osDelay(1);
		HAL_GPIO_WritePin(WDI_GPIO_Port,WDI_Pin,GPIO_PIN_RESET);
		delay++;
		if(delay>=100)
		{
			delay = 0;
			HAL_GPIO_TogglePin(S2_R_GPIO_Port,S2_R_Pin);
		}
  }
  /* USER CODE END StartDefaultTask */
}

/************************ (C) COPYRIGHT STMicroelectronics *****END OF FILE****/
